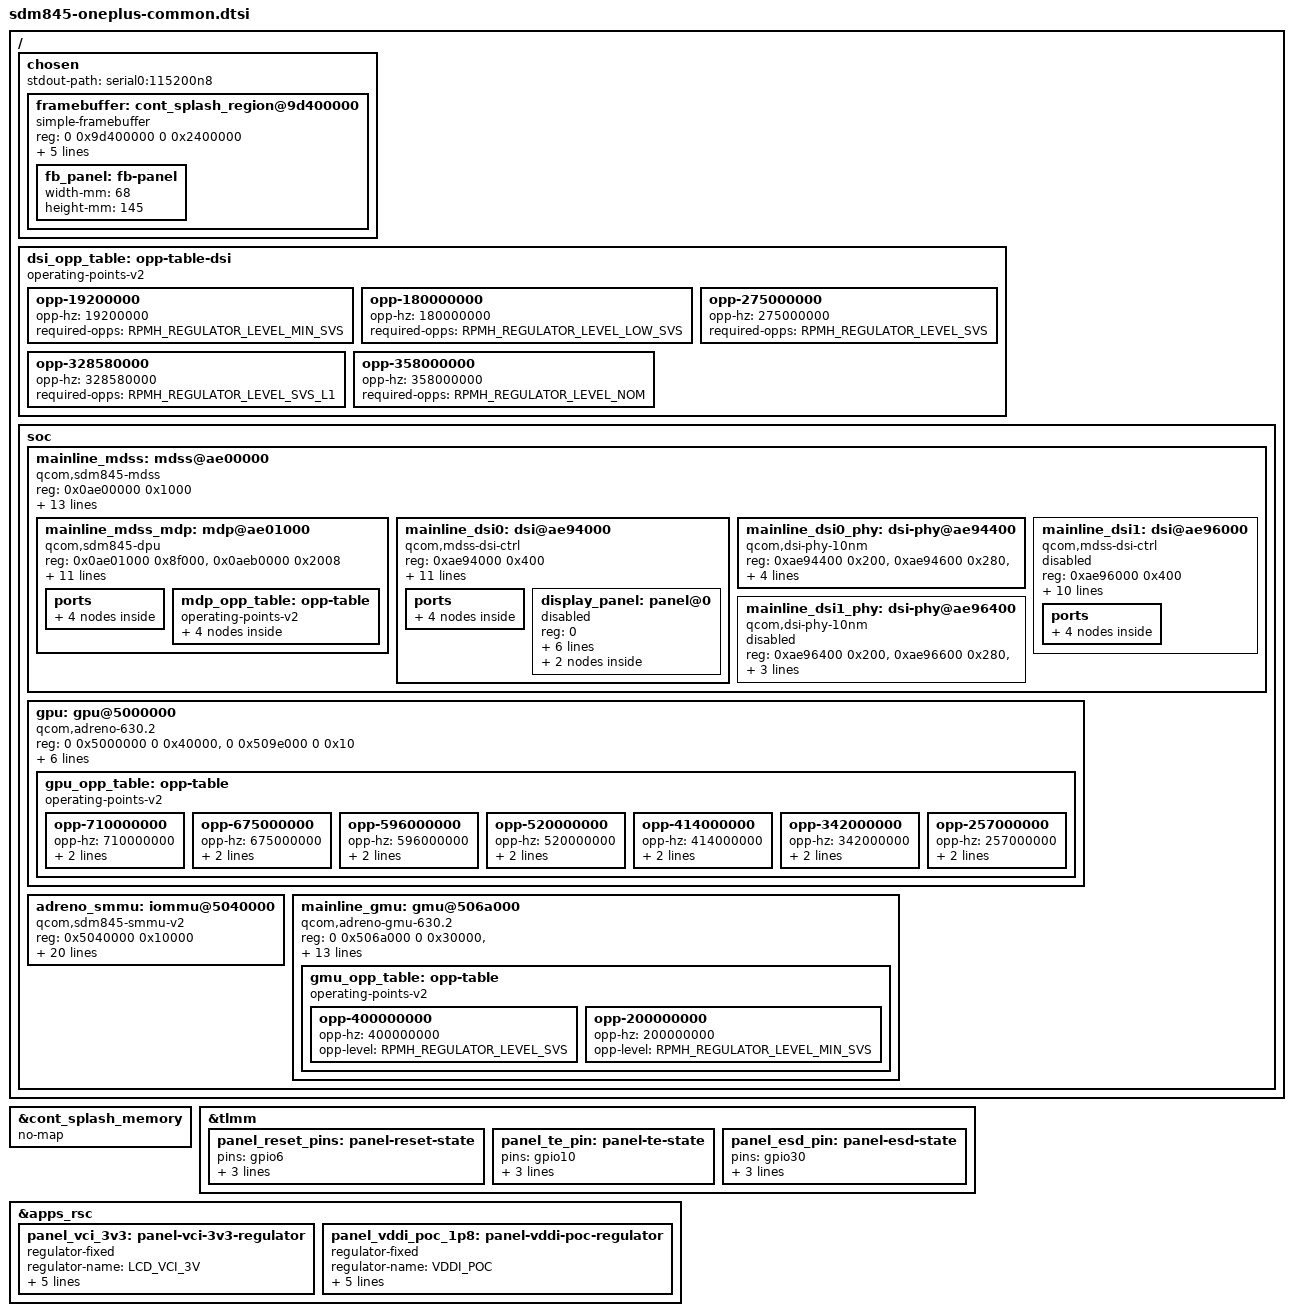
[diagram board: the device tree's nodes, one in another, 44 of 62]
/dts-v1/;
#include <dt-bindings/clock/qcom,gcc-sdm845.h>
#include <dt-bindings/clock/qcom,dispcc-sdm845.h>
#include <dt-bindings/clock/qcom,gpucc-sdm845.h>
#include <dt-bindings/clock/qcom,rpmh.h>
#include <dt-bindings/regulator/qcom,rpmh-regulator-levels.h>
#include <dt-bindings/interrupt-controller/arm-gic.h>
#include <dt-bindings/spmi/spmi.h>
#include <dt-bindings/soc/qcom,dcc_v2.h>
#include <dt-bindings/msm/msm-bus-ids.h>

/ {
	chosen {
		#address-cells = <2>;
		#size-cells = <2>;
		ranges;

		stdout-path = "serial0:115200n8";

		framebuffer: cont_splash_region@9d400000 {
			compatible = "simple-framebuffer";
			reg = <0 0x9d400000 0 0x2400000>;
			width = <1080>;
			height = <2280>;
			stride = <(1080 * 4)>;
			format = "a8r8g8b8";

			/**
			 * HACK:
			 * Fake panel node for simple-framebuffer to calculate DPI from. Only
			 * needs width & height specified. This allows us to break device link
			 * from simplefb to mdss (implicitly via panel->mdp->mdss) to fix drm
			 * device probe ordering. Without this, simpledrm would probe second
			 * after msm-drm, and confuse userspace with 2 GPUs in /dev/dri.
			 * Alternative workaround is to boot with kernel parameter
			 * `fw_devlink=permissive`, which is worse, because it can hide other
			 * issues with device dependencies.
			 */
			panel = <&fb_panel>;

			fb_panel: fb-panel {
				width-mm = <68>;
				height-mm = <145>;
			};
		};
	};
};

/ {
	dsi_opp_table: opp-table-dsi {
		compatible = "operating-points-v2";

		opp-19200000 {
			opp-hz = /bits/ 64 <19200000>;
			required-opps = <RPMH_REGULATOR_LEVEL_MIN_SVS>;
		};

		opp-180000000 {
			opp-hz = /bits/ 64 <180000000>;
			required-opps = <RPMH_REGULATOR_LEVEL_LOW_SVS>;
		};

		opp-275000000 {
			opp-hz = /bits/ 64 <275000000>;
			required-opps = <RPMH_REGULATOR_LEVEL_SVS>;
		};

		opp-328580000 {
			opp-hz = /bits/ 64 <328580000>;
			required-opps = <RPMH_REGULATOR_LEVEL_SVS_L1>;
		};

		opp-358000000 {
			opp-hz = /bits/ 64 <358000000>;
			required-opps = <RPMH_REGULATOR_LEVEL_NOM>;
		};
	};
};

/ {
	soc {
		mainline_mdss: mdss@ae00000 {
			compatible = "qcom,sdm845-mdss";
			reg = <0x0ae00000 0x1000>;
			reg-names = "mdss";

			power-domains = <&clock_dispcc MDSS_GDSC>;

			//resets = <&clock_gcc GCC_MMSS_BCR>;

			clocks = <&clock_dispcc DISP_CC_MDSS_AHB_CLK>,
				 <&clock_dispcc DISP_CC_MDSS_MDP_CLK>;
			clock-names = "iface", "core";

			assigned-clocks = <&clock_dispcc DISP_CC_MDSS_MDP_CLK>;
			assigned-clock-rates = <300000000>;

			interrupts = <GIC_SPI 83 IRQ_TYPE_LEVEL_HIGH>;
			interrupt-controller;
			#interrupt-cells = <1>;

			interconnects = <MSM_BUS_MASTER_MDP_PORT0 MSM_BUS_SLAVE_EBI_CH0>,
					<MSM_BUS_MASTER_MDP_PORT1 MSM_BUS_SLAVE_EBI_CH0>;

			iommus = <&apps_smmu 0x880 0x8>,
					 <&apps_smmu 0xc80 0x8>;

			status = "okay";

			#address-cells = <1>;
			#size-cells = <1>;
			ranges;

			mainline_mdss_mdp: mdp@ae01000 {
				compatible = "qcom,sdm845-dpu";

				reg = <0x0ae01000 0x8f000>,
					  <0x0aeb0000 0x2008>;
				reg-names = "mdp", "vbif";

				clocks = <&clock_gcc GCC_DISP_AXI_CLK>,
					 <&clock_dispcc DISP_CC_MDSS_AHB_CLK>,
					 <&clock_dispcc DISP_CC_MDSS_AXI_CLK>,
					 <&clock_dispcc DISP_CC_MDSS_MDP_CLK>,
					 <&clock_dispcc DISP_CC_MDSS_VSYNC_CLK>;
				clock-names = "gcc-bus", "iface", "bus", "core", "vsync";

				assigned-clocks = <&clock_dispcc DISP_CC_MDSS_VSYNC_CLK>;
				assigned-clock-rates = <19200000>;
				operating-points-v2 = <&mdp_opp_table>;

				interrupt-parent = <&mainline_mdss>;
				interrupts = <0 IRQ_TYPE_LEVEL_HIGH>;

				status = "okay";

				ports {
					#address-cells = <1>;
					#size-cells = <0>;

					port@0 {
						reg = <0>;
						dpu_intf1_out: endpoint {
							remote-endpoint = <&mainline_dsi0_in>;
						};
					};

					port@1 {
						reg = <1>;
						dpu_intf2_out: endpoint {
							remote-endpoint = <&mainline_dsi1_in>;
						};
					};

				};

				mdp_opp_table: opp-table {
					compatible = "operating-points-v2";

					opp-19200000 {
						opp-hz = /bits/ 64 <19200000>;
						required-opps = <RPMH_REGULATOR_LEVEL_MIN_SVS>;
					};

					opp-171428571 {
						opp-hz = /bits/ 64 <171428571>;
						required-opps = <RPMH_REGULATOR_LEVEL_LOW_SVS>;
					};

					opp-344000000 {
						opp-hz = /bits/ 64 <344000000>;
						required-opps = <RPMH_REGULATOR_LEVEL_SVS_L1>;
					};

					opp-430000000 {
						opp-hz = /bits/ 64 <430000000>;
						required-opps = <RPMH_REGULATOR_LEVEL_NOM>;
					};
				};
			};

			mainline_dsi0: dsi@ae94000 {
				compatible = "qcom,mdss-dsi-ctrl";
				reg = <0xae94000 0x400>;
				reg-names = "dsi_ctrl";

				interrupt-parent = <&mainline_mdss>;
				interrupts = <4 IRQ_TYPE_LEVEL_HIGH>;

				clocks = <&clock_dispcc DISP_CC_MDSS_BYTE0_CLK>,
					 <&clock_dispcc DISP_CC_MDSS_BYTE0_INTF_CLK>,
					 <&clock_dispcc DISP_CC_MDSS_PCLK0_CLK>,
					 <&clock_dispcc DISP_CC_MDSS_ESC0_CLK>,
					 <&clock_dispcc DISP_CC_MDSS_AHB_CLK>,
					 <&clock_dispcc DISP_CC_MDSS_AXI_CLK>;
				clock-names = "byte",
						  "byte_intf",
						  "pixel",
						  "core",
						  "iface",
						  "bus";

				operating-points-v2 = <&dsi_opp_table>;
				phys = <&mainline_dsi0_phy>;
				phy-names = "dsi";

				status = "okay";

				ports {
					#address-cells = <1>;
					#size-cells = <0>;

					port@0 {
						reg = <0>;
						mainline_dsi0_in: endpoint {
							remote-endpoint = <&dpu_intf1_out>;
						};
					};

					port@1 {
						reg = <1>;
						mainline_dsi0_out: endpoint {
						};
					};
				};
			};

			mainline_dsi0_phy: dsi-phy@ae94400 {
				compatible = "qcom,dsi-phy-10nm";

				reg = <0xae94400 0x200>,
					  <0xae94600 0x280>,
					  <0xae94a00 0x1e0>;

				reg-names = "dsi_phy",
						"dsi_phy_lane",
						"dsi_pll";

				#clock-cells = <1>;
				#phy-cells = <0>;

				clocks = <&clock_dispcc DISP_CC_MDSS_AHB_CLK>,
					 <&clock_rpmh RPMH_CXO_CLK>;
				clock-names = "iface", "ref";

				status = "okay";
			};

			mainline_dsi1: dsi@ae96000 {
				compatible = "qcom,mdss-dsi-ctrl";
				reg = <0xae96000 0x400>;
				reg-names = "dsi_ctrl";

				interrupt-parent = <&mainline_mdss>;
				interrupts = <5 IRQ_TYPE_LEVEL_HIGH>;

				clocks = <&clock_dispcc DISP_CC_MDSS_BYTE1_CLK>,
					 <&clock_dispcc DISP_CC_MDSS_BYTE1_INTF_CLK>,
					 <&clock_dispcc DISP_CC_MDSS_PCLK1_CLK>,
					 <&clock_dispcc DISP_CC_MDSS_ESC1_CLK>,
					 <&clock_dispcc DISP_CC_MDSS_AHB_CLK>,
					 <&clock_dispcc DISP_CC_MDSS_AXI_CLK>;
				clock-names = "byte",
						  "byte_intf",
						  "pixel",
						  "core",
						  "iface",
						  "bus";

				operating-points-v2 = <&dsi_opp_table>;
				phys = <&mainline_dsi1_phy>;
				phy-names = "dsi";

				status = "disabled";

				ports {
					#address-cells = <1>;
					#size-cells = <0>;

					port@0 {
						reg = <0>;
						mainline_dsi1_in: endpoint {
							remote-endpoint = <&dpu_intf2_out>;
						};
					};

					port@1 {
						reg = <1>;
						mainline_dsi1_out: endpoint {
						};
					};

				};
			};

			mainline_dsi1_phy: dsi-phy@ae96400 {
				compatible = "qcom,dsi-phy-10nm";

				reg = <0xae96400 0x200>,
					  <0xae96600 0x280>,
					  <0xae96a00 0x10e>;

				reg-names = "dsi_phy",
						"dsi_phy_lane",
						"dsi_pll";

				#clock-cells = <1>;
				#phy-cells = <0>;

				clocks = <&clock_dispcc DISP_CC_MDSS_AHB_CLK>,
					 <&clock_rpmh RPMH_CXO_CLK>;
				clock-names = "iface", "ref";

				status = "disabled";
			};
		};

		gpu: gpu@5000000 {
			compatible = "qcom,adreno-630.2", "qcom,adreno";

			reg = <0 0x5000000 0 0x40000>, <0 0x509e000 0 0x10>;
			reg-names = "kgsl_3d0_reg_memory", "cx_mem";

			/*
			 * Look ma, no clocks! The GPU clocks and power are
			 * controlled entirely by the GMU
			 */

			interrupts = <GIC_SPI 300 IRQ_TYPE_LEVEL_HIGH>;

			iommus = <&adreno_smmu 0>;

			operating-points-v2 = <&gpu_opp_table>;

			qcom,gmu = <&mainline_gmu>;

			interconnects = <MSM_BUS_MASTER_GRAPHICS_3D MSM_BUS_SLAVE_EBI_CH0>;

			gpu_opp_table: opp-table {
				compatible = "operating-points-v2";

				opp-710000000 {
					opp-hz = /bits/ 64 <710000000>;
					opp-level = <RPMH_REGULATOR_LEVEL_TURBO_L1>;
					opp-peak-kBps = <7216000>;
				};

				opp-675000000 {
					opp-hz = /bits/ 64 <675000000>;
					opp-level = <RPMH_REGULATOR_LEVEL_TURBO>;
					opp-peak-kBps = <7216000>;
				};

				opp-596000000 {
					opp-hz = /bits/ 64 <596000000>;
					opp-level = <RPMH_REGULATOR_LEVEL_NOM_L1>;
					opp-peak-kBps = <6220000>;
				};

				opp-520000000 {
					opp-hz = /bits/ 64 <520000000>;
					opp-level = <RPMH_REGULATOR_LEVEL_NOM>;
					opp-peak-kBps = <6220000>;
				};

				opp-414000000 {
					opp-hz = /bits/ 64 <414000000>;
					opp-level = <RPMH_REGULATOR_LEVEL_SVS_L1>;
					opp-peak-kBps = <4068000>;
				};

				opp-342000000 {
					opp-hz = /bits/ 64 <342000000>;
					opp-level = <RPMH_REGULATOR_LEVEL_SVS>;
					opp-peak-kBps = <2724000>;
				};

				opp-257000000 {
					opp-hz = /bits/ 64 <257000000>;
					opp-level = <RPMH_REGULATOR_LEVEL_LOW_SVS>;
					opp-peak-kBps = <1648000>;
				};
			};
		};

		adreno_smmu: iommu@5040000 {
			compatible = "qcom,sdm845-smmu-v2", "qcom,smmu-v2";
			status = "ok";
			reg = <0x5040000 0x10000>;
			#iommu-cells = <1>;
			#global-interrupts = <2>;
			interrupts = <GIC_SPI 229 IRQ_TYPE_LEVEL_HIGH>,
					 <GIC_SPI 231 IRQ_TYPE_LEVEL_HIGH>,
					 <GIC_SPI 364 IRQ_TYPE_EDGE_RISING>,
					 <GIC_SPI 365 IRQ_TYPE_EDGE_RISING>,
					 <GIC_SPI 366 IRQ_TYPE_EDGE_RISING>,
					 <GIC_SPI 367 IRQ_TYPE_EDGE_RISING>,
					 <GIC_SPI 368 IRQ_TYPE_EDGE_RISING>,
					 <GIC_SPI 369 IRQ_TYPE_EDGE_RISING>,
					 <GIC_SPI 370 IRQ_TYPE_EDGE_RISING>,
					 <GIC_SPI 371 IRQ_TYPE_EDGE_RISING>;

			clocks= <&clock_gcc GCC_GPU_MEMNOC_GFX_CLK>,
				   <&clock_gcc GCC_GPU_CFG_AHB_CLK>;
			clock-names = "bus", "iface";
			/**
			 * HACK: Instead of backporting a new SMMU management
			 * just so downstream 4.19 just to manage CXPD voting
			 * from smmu. we can just wire it to the expected
			 * regulator and it will be manage it.
			 */
			qcom,regulator-names = "vdd";
			vdd-supply = <&gpu_cx_gdsc>;

			/* CB5(ATOS) & CB5/6/7 are protected by HYP */
			qcom,protect = <0x40000 0xc000>;
			qcom,micro-mmu-control = <0x6000>;
			qcom,secure_align_mask = <0xfff>;
			qcom,retention;
			qcom,hyp_secure_alloc;
		};

		mainline_gmu: gmu@506a000 {
			compatible="qcom,adreno-gmu-630.2", "qcom,adreno-gmu";
			reg = <0 0x506a000 0 0x30000>,
				  <0 0xb280000 0 0x10000>,
				  <0 0xb480000 0 0x10000>;
			reg-names = "gmu", "gmu_pdc", "gmu_pdc_seq";

			interrupts = <GIC_SPI 304 IRQ_TYPE_LEVEL_HIGH>,
					 <GIC_SPI 305 IRQ_TYPE_LEVEL_HIGH>;
			interrupt-names = "hfi", "gmu";

			clocks = <&clock_gpucc GPU_CC_CX_GMU_CLK>,
					<&clock_gpucc GPU_CC_CXO_CLK>,
					<&clock_gcc GCC_DDRSS_GPU_AXI_CLK>,
					<&clock_gcc GCC_GPU_MEMNOC_GFX_CLK>;

			clock-names = "gmu", "cxo", "axi", "memnoc";

			power-domains = <&clock_gpucc GPU_CX_GDSC>,
							<&clock_gpucc GPU_GX_GDSC>;
			power-domain-names = "cx", "gx";


			dma-ranges = <0 0x60000000 0 0x60000000 0 0x20000000>;

			iommus = <&adreno_smmu 5>;

			operating-points-v2 = <&gmu_opp_table>;

			gmu_opp_table: opp-table {
				compatible = "operating-points-v2";

				opp-400000000 {
					opp-hz = /bits/ 64 <400000000>;
					opp-level = <RPMH_REGULATOR_LEVEL_SVS>;
				};

				opp-200000000 {
					opp-hz = /bits/ 64 <200000000>;
					opp-level = <RPMH_REGULATOR_LEVEL_MIN_SVS>;
				};
			};
		};
	};
};

#include "sdm845-v2.1.dtsi"

&cont_splash_memory {
    no-map;
};

#define POWER_NODE(label)    &label { #power-domain-cells = <1>; }

POWER_NODE(clock_dispcc);
POWER_NODE(clock_gcc);
POWER_NODE(clock_gpucc);

&tlmm {
	panel_reset_pins: panel-reset-state {
		pins = "gpio6";
		function = "gpio";
		drive-strength = <8>;
		bias-disable;
	};

	panel_te_pin: panel-te-state {
		pins = "gpio10";
		function = "mdp_vsync";
		drive-strength = <2>;
		bias-disable;
	};

	panel_esd_pin: panel-esd-state {
		pins = "gpio30";
		function = "gpio";
		drive-strength = <2>;
		bias-pull-down;
	};
};

&apps_rsc {
	panel_vci_3v3: panel-vci-3v3-regulator {
		compatible = "regulator-fixed";
		regulator-name = "LCD_VCI_3V";

		regulator-min-microvolt = <3300000>;
		regulator-max-microvolt = <3300000>;

		gpio = <&tlmm 26 GPIO_ACTIVE_HIGH>;
		enable-active-high;
		regulator-boot-on;
	};

	panel_vddi_poc_1p8: panel-vddi-poc-regulator {
		compatible = "regulator-fixed";
		regulator-name = "VDDI_POC";

		regulator-min-microvolt = <1800000>;
		regulator-max-microvolt = <1800000>;

		gpio = <&tlmm 25 GPIO_ACTIVE_HIGH>;
		enable-active-high;
		regulator-boot-on;
	};
};

&mainline_dsi0 {
	status = "okay";

	vdda-supply = <&pm8998_l26>;

	#address-cells = <1>;
	#size-cells = <0>;

	/*
	 * Both devices use different panels but all other properties
	 * are common. Compatible line is declared in device dts.
	 */
	display_panel: panel@0 {
		status = "disabled";

		#address-cells = <1>;
		#size-cells = <0>;
		reg = <0>;

		vddio-supply = <&pm8998_l14>;
		vci-supply = <&panel_vci_3v3>;
		poc-supply = <&panel_vddi_poc_1p8>;

		reset-gpios = <&tlmm 6 GPIO_ACTIVE_LOW>;

		pinctrl-names = "default";

		pinctrl-0 = <&panel_reset_pins &panel_te_pin &panel_esd_pin>;

		port {
			panel_in: endpoint {
				remote-endpoint = <&mainline_dsi0_out>;
			};
		};
	};
};

&mainline_dsi0_out {
	remote-endpoint = <&panel_in>;
	data-lanes = <0 1 2 3>;
};

&mainline_dsi0_phy {
	vdds-supply = <&pm8998_l1>;
};

#define DISABLE_NODE(label)    &label { status = "disabled"; }

/*
 * Disable SDE.
 */
DISABLE_NODE(mdss_mdp);
DISABLE_NODE(sde_rscc);
DISABLE_NODE(mdss_rotator);
DISABLE_NODE(mdss_dsi0);
DISABLE_NODE(mdss_dsi1);
DISABLE_NODE(mdss_dsi_phy0);
DISABLE_NODE(mdss_dsi_phy1);
DISABLE_NODE(sde_dp);

/*
 * Disable KGSL.
 */
DISABLE_NODE(msm_bus);
DISABLE_NODE(pil_gpu);
DISABLE_NODE(gpu_bw_tbl);
DISABLE_NODE(msm_gpu);
DISABLE_NODE(gpubw);
DISABLE_NODE(kgsl_msm_iommu);
DISABLE_NODE(gmu);

/*
 * disable KGSL SMMU.
*/

DISABLE_NODE(kgsl_smmu);

/*
 * Disable SDE PIL
 */
DISABLE_NODE(mdss_dsi0_pll);
DISABLE_NODE(mdss_dp_pll);

/*
 * Disable SDE Display (if needed)
 */
/*
DISABLE_NODE(dsi_panel_pwr_supply);
DISABLE_NODE(dsi_panel_pwr_supply_no_labibb);
DISABLE_NODE(dsi_panel_pwr_supply_vdd_no_labibb);
DISABLE_NODE(sde_dsi);
DISABLE_NODE(sde_wb);
DISABLE_NODE(ext_disp);
*/
